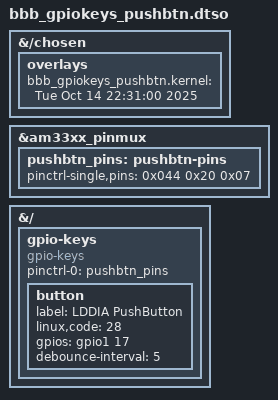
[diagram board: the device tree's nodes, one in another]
/*
 * bbb_gpiokeys_pushbtn.dts
 ***************************************************************
 * This program is part of the source code released for the book
 *  "Linux Device Drivers In Action"
 *  (c) Author: Kaiwan N Billimoria
 *  Publisher:  Packt
 *  GitHub repository:
 *  https://github.com/PacktPublishing/Learn-Linux-Device-Drivers
 *
 * From: Ch 10 : Writing an Input Device Driver
 ****************************************************************
 * Intent: to use the kernel's builtin gpio-keys driver to make our simple
 * GPIO-based pushbutton input device work!
 * By setting up this DT overlay, we tell it about our pushbutton; it auto
 * sets up the IRQ line mapped to the GPIO.
 *
 * NOTE: this particular DT overlay is designed for only the TI BBB.
 * Try it out:
 *  make ; make install
 *  update /boot/uEnv.txt
 *  reboot
 *  test via sudo evtest
 *
 * For details, please refer the book, Ch 10.
 * (c) Kaiwan N Billimoria, kaiwanTECH
 * License: Dual MIT/GPL
 */
/dts-v1/;
/plugin/;

/*
 * Helper to show loaded overlays under: /proc/device-tree/chosen/overlays/
 */
&{/chosen} {
	overlays {
		bbb_gpiokeys_pushbtn.kernel = "Tue Oct 14 22:31:00 2025";
		  /* This should be '__TIMESTAMP__' but that's defined in kernel src only..
		   * So have simply hardcoded it here to some random timestamp
		   */
	};
};

/*
 * VERY IMP
 * Typically, two sections of the DT (Overlay) need configuration:
 * - the PinMux, in order to make the required pin(s) functionality visible on
 *   the CPU/SoC pads, and
 * - the device itself, in order to launch and configure its device driver
 */

/*
 * We want to keep it simple and be able to compile the DTSO locally; this
 * implies that we can't use the kernel-tree macros; so we just use literals
 * but show the macros in the comment below. 
 * DON'T do it like this in production!
 */
&am33xx_pinmux {
	pushbtn_pins: pushbtn-pins {
		/* Wrt board (BBB) pin: P9_23 
		 *   = GPMC_A1 = GPIO1_17  (BBB SRM)
		 * Interpreting < 0x044 0x20 0x07 >;
		 * 0x044 = AM335X_PIN_GPMC_A1 (0x844 - 0x800)   (AM335X TRM)
		 * 0x20 = PIN_INPUT_PULLDOWN
		 * 0x07 = MUX_MODE7
		 */
		pinctrl-single,pins = < 0x044 0x20 0x07 >;
		//pinctrl-single,pins = < 0x078 0x27 >; // older 2-cell style
	};
};

&{/} {
	gpio-keys {
		compatible = "gpio-keys";
		pinctrl-names = "default";
		pinctrl-0 = <&pushbtn_pins>;  /* link to the PinMux */
		button {
			label = "LDDIA PushButton";
			linux,code = <28>;      /* KEY_ENTER */
			gpios = <&gpio1 17 0>;  /* 0 = GPIO_ACTIVE_HIGH */
			debounce-interval = <5>;
		};
	};
};
